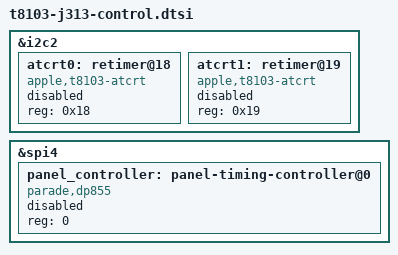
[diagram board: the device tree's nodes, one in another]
// SPDX-License-Identifier: GPL-2.0+ OR MIT
/* Populated board control clients. Transport ownership is not transferred. */

&i2c2 {
	atcrt0: retimer@18 {
		compatible = "apple,t8103-atcrt", "apple,atcrt";
		reg = <0x18>;
		status = "disabled";
	};

	atcrt1: retimer@19 {
		compatible = "apple,t8103-atcrt", "apple,atcrt";
		reg = <0x19>;
		status = "disabled";
	};
};

&spi4 {
	panel_controller: panel-timing-controller@0 {
		compatible = "parade,dp855";
		reg = <0>;
		status = "disabled";
	};
};
